# SPI5 register map
Registers from a debugger description file.
Registers are 32-bit, access not given, no defined reset value unless marked. A register's access mark holds for its fields unless they carry their own. Addresses are absolute; registers are grouped by the start of their names; lines under a group give offsets from that group; [hi:lo] are bit positions; {n}, {i} and the like mark numbered series; 'fields as' and 'values as' point back to an identical list; <NAME> marks a mode.

## SPI5
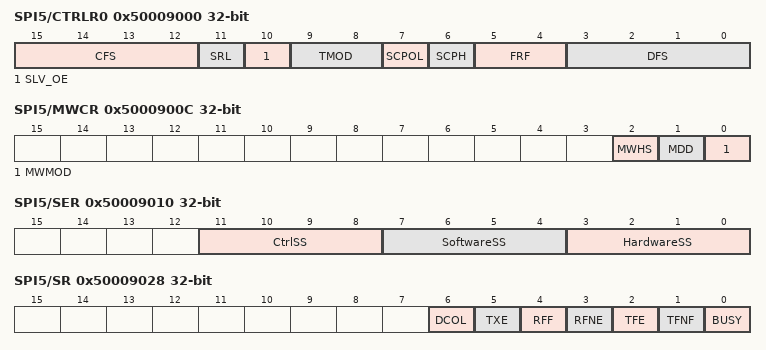
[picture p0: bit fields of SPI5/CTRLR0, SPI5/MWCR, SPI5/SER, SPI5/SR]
0x50009000 SPI5/CTRLR0
  [15:12] CFS, [11] SRL, [10] SLV_OE, [9:8] TMOD, [7] SCPOL, [6] SCPH, [5:4] FRF, [3:0] DFS
0x50009004 SPI5/CTRLR1
  [15:0] NDF
0x50009008 SPI5/SSIENR
  [0] SSIENR
0x5000900C SPI5/MWCR
  [2] MWHS, [1] MDD, [0] MWMOD
0x50009010 SPI5/SER
  [11:8] CtrlSS, [7:4] SoftwareSS, [3:0] HardwareSS
0x50009014 SPI5/BAUDR
  [15:0] SCKDV
0x50009018 SPI5/TXFTLR
  [3:0] TFT
0x5000901C SPI5/RXFTLR
  [3:0] RFT
0x50009020 SPI5/TXFLR ro
  [3:0] TXTFL
0x50009024 SPI5/RXFLR ro
  [3:0] RXTFL
0x50009028 SPI5/SR ro
  [6] DCOL, [5] TXE, [4] RFF, [3] RFNE, [2] TFE, [1] TFNF, [0] BUSY
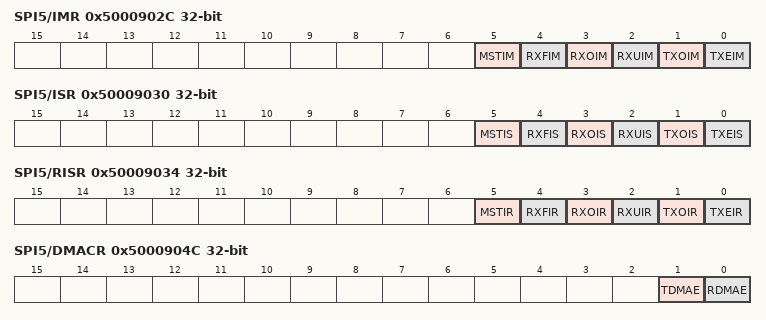
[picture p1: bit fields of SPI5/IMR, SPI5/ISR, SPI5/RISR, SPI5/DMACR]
0x5000902C SPI5/IMR
  [5] MSTIM, [4] RXFIM, [3] RXOIM, [2] RXUIM, [1] TXOIM, [0] TXEIM
0x50009030 SPI5/ISR ro
  [5] MSTIS, [4] RXFIS, [3] RXOIS, [2] RXUIS, [1] TXOIS, [0] TXEIS
0x50009034 SPI5/RISR ro
  [5] MSTIR, [4] RXFIR, [3] RXOIR, [2] RXUIR, [1] TXOIR, [0] TXEIR
0x50009038 SPI5/TXOICR ro
  [0] TXOICR
0x5000903C SPI5/RXOICR ro
  [0] RXOICR
0x50009040 SPI5/RXUICR ro
  [0] RXUICR
0x50009044 SPI5/MSTICR ro
  [0] MSTICR
0x50009048 SPI5/ICR ro
  [0] ICR
0x5000904C SPI5/DMACR
  [1] TDMAE, [0] RDMAE
0x50009050 SPI5/DMATDLR
  [3:0] DMATDLR
0x50009054 SPI5/DMARDLR
  [3:0] DMARDLR
0x50009058 SPI5/IDR ro
  [31:0] ICR
0x5000905C SPI5/SSI_COMP_VERSION ro
0x50009060 SPI5/DR
  [15:0] DR
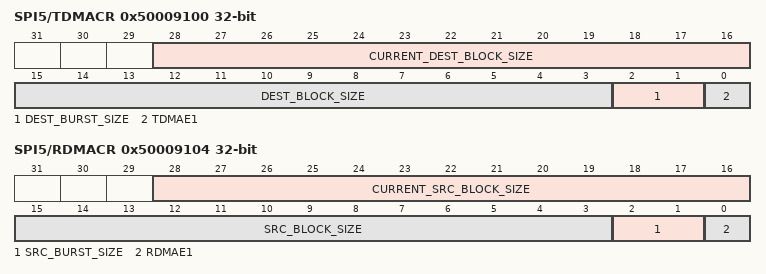
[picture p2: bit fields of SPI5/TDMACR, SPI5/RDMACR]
0x50009100 SPI5/TDMACR
  [28:16] CURRENT_DEST_BLOCK_SIZE, [15:3] DEST_BLOCK_SIZE, [2:1] DEST_BURST_SIZE, [0] TDMAE1
0x50009104 SPI5/RDMACR
  [28:16] CURRENT_SRC_BLOCK_SIZE, [15:3] SRC_BLOCK_SIZE, [2:1] SRC_BURST_SIZE, [0] RDMAE1
